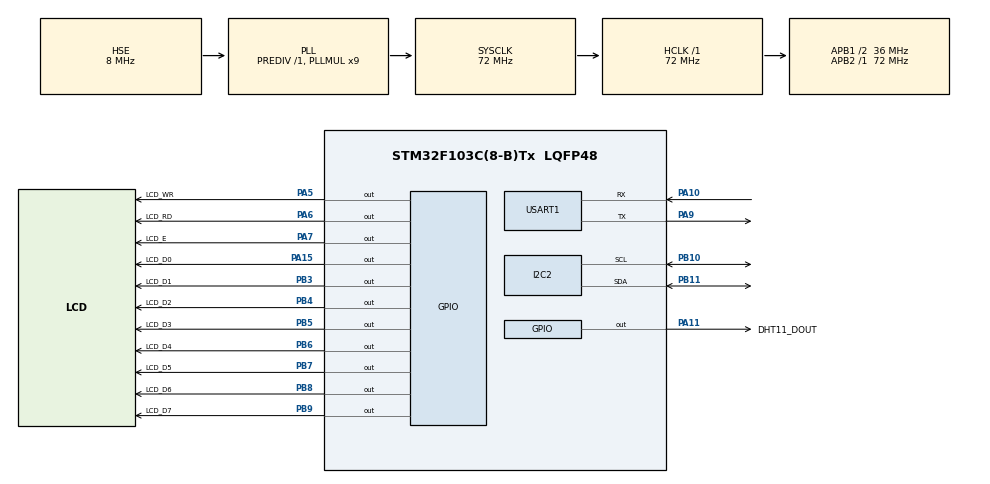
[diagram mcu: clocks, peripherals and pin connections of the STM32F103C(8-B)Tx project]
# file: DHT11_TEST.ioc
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Mcu.Family=STM32F1
Mcu.Name=STM32F103C(8-B)Tx
Mcu.Package=LQFP48
NVIC.PriorityGroup=NVIC_PRIORITYGROUP_4
NVIC.TIM2_IRQn=true\:0\:0\:false\:false\:true\:true\:true
PA10.Mode=Asynchronous
PA10.Signal=USART1_RX
PA11.GPIO_Label=DHT11_DOUT
PA11.GPIO_ModeDefaultOutputPP=GPIO_MODE_OUTPUT_OD
PA11.Signal=GPIO_Output
PA15.GPIO_Label=LCD_D0
PA15.Signal=GPIO_Output
PA5.GPIO_Label=LCD_WR
PA5.Signal=GPIO_Output
PA6.GPIO_Label=LCD_RD
PA6.Signal=GPIO_Output
PA7.GPIO_Label=LCD_E
PA7.Signal=GPIO_Output
PA9.Mode=Asynchronous
PA9.Signal=USART1_TX
PB10.Mode=I2C
PB10.Signal=I2C2_SCL
PB11.Mode=I2C
PB11.Signal=I2C2_SDA
PB3.GPIO_Label=LCD_D1
PB3.Signal=GPIO_Output
PB4.GPIO_Label=LCD_D2
PB4.Signal=GPIO_Output
PB5.GPIO_Label=LCD_D3
PB5.Signal=GPIO_Output
PB6.GPIO_Label=LCD_D4
PB6.Signal=GPIO_Output
PB7.GPIO_Label=LCD_D5
PB7.Signal=GPIO_Output
PB8.GPIO_Label=LCD_D6
PB8.Signal=GPIO_Output
PB9.GPIO_Label=LCD_D7
PB9.Signal=GPIO_Output
PD0-OSC_IN.Mode=HSE-External-Oscillator
PD0-OSC_IN.Signal=RCC_OSC_IN
PD1-OSC_OUT.Mode=HSE-External-Oscillator
PD1-OSC_OUT.Signal=RCC_OSC_OUT
ProjectManager.HeapSize=0x200
ProjectManager.StackSize=0x400
ProjectManager.TargetToolchain=STM32CubeIDE
RCC.AHBFreq_Value=72000000
RCC.APB1CLKDivider=RCC_HCLK_DIV2
RCC.APB1Freq_Value=36000000
RCC.APB1TimFreq_Value=72000000
RCC.APB2Freq_Value=72000000
RCC.APB2TimFreq_Value=72000000
RCC.HCLKFreq_Value=72000000
RCC.PLLMUL=RCC_PLL_MUL9
RCC.PLLSourceVirtual=RCC_PLLSOURCE_HSE
RCC.SYSCLKFreq_VALUE=72000000
RCC.SYSCLKSource=RCC_SYSCLKSOURCE_PLLCLK
RCC.USBFreq_Value=72000000
USART1.VirtualMode=VM_ASYNC
VP_SYS_VS_ND.Mode=No_Debug
VP_TIM2_VS_ClockSourceINT.Mode=Internal
board=custom

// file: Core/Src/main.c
/* USER CODE BEGIN Header */
/**
  ******************************************************************************
  * @file           : main.c
  * @brief          : Main program body
  ******************************************************************************
  * @attention
  *
  * <h2><center>&copy; Copyright (c) 2020 STMicroelectronics.
  * All rights reserved.</center></h2>
  *
  * This software component is licensed by ST under BSD 3-Clause license,
  * the "License"; You may not use this file except in compliance with the
  * License. You may obtain a copy of the License at:
  *                        opensource.org/licenses/BSD-3-Clause
  *
  ******************************************************************************
  */
/* USER CODE END Header */
#include "main.h"

I2C_HandleTypeDef hi2c2;

TIM_HandleTypeDef htim2;

UART_HandleTypeDef huart1;

/* USER CODE BEGIN PV */
extern uint8_t dht11_data[5];
/* USER CODE END PV */

void SystemClock_Config(void);
static void MX_GPIO_Init(void);
static void MX_I2C2_Init(void);
static void MX_TIM2_Init(void);
static void MX_USART1_UART_Init(void);

int main(void)
{

  /* MCU Configuration--------------------------------------------------------*/

  /* Reset of all peripherals, Initializes the Flash interface and the Systick. */
  HAL_Init();

  /* Configure the system clock */
  SystemClock_Config();

  /* Initialize all configured peripherals */
  MX_GPIO_Init();
  MX_I2C2_Init();
  MX_TIM2_Init();
  MX_USART1_UART_Init();
  /* USER CODE BEGIN 2 */

  lcd_init();
  /* USER CODE END 2 */

  /* Infinite loop */
  while (1)
  {

	  lcd_writeCom(0x80);

	  DHT11_read();
	  lcd_show_dht11(dht11_data);

	  lcd_writeCom(0x80|0x40);

	  lcd_show_gy30(GY30_read());

	  HAL_Delay(1000);
  }
}

void SystemClock_Config(void)
{
  RCC_OscInitTypeDef RCC_OscInitStruct = {0};
  RCC_ClkInitTypeDef RCC_ClkInitStruct = {0};

  /** Initializes the RCC Oscillators according to the specified parameters
  * in the RCC_OscInitTypeDef structure.
  */
  RCC_OscInitStruct.OscillatorType = RCC_OSCILLATORTYPE_HSE;
  RCC_OscInitStruct.HSEState = RCC_HSE_ON;
  RCC_OscInitStruct.HSEPredivValue = RCC_HSE_PREDIV_DIV1;
  RCC_OscInitStruct.HSIState = RCC_HSI_ON;
  RCC_OscInitStruct.PLL.PLLState = RCC_PLL_ON;
  RCC_OscInitStruct.PLL.PLLSource = RCC_PLLSOURCE_HSE;
  RCC_OscInitStruct.PLL.PLLMUL = RCC_PLL_MUL9;
  if (HAL_RCC_OscConfig(&RCC_OscInitStruct) != HAL_OK)
  {
    Error_Handler();
  }
  /** Initializes the CPU, AHB and APB buses clocks
  */
  RCC_ClkInitStruct.ClockType = RCC_CLOCKTYPE_HCLK|RCC_CLOCKTYPE_SYSCLK
                              |RCC_CLOCKTYPE_PCLK1|RCC_CLOCKTYPE_PCLK2;
  RCC_ClkInitStruct.SYSCLKSource = RCC_SYSCLKSOURCE_PLLCLK;
  RCC_ClkInitStruct.AHBCLKDivider = RCC_SYSCLK_DIV1;
  RCC_ClkInitStruct.APB1CLKDivider = RCC_HCLK_DIV2;
  RCC_ClkInitStruct.APB2CLKDivider = RCC_HCLK_DIV1;

  if (HAL_RCC_ClockConfig(&RCC_ClkInitStruct, FLASH_LATENCY_2) != HAL_OK)
  {
    Error_Handler();
  }
}

static void MX_I2C2_Init(void)
{

  hi2c2.Instance = I2C2;
  hi2c2.Init.ClockSpeed = 100000;
  hi2c2.Init.DutyCycle = I2C_DUTYCYCLE_2;
  hi2c2.Init.OwnAddress1 = 0;
  hi2c2.Init.AddressingMode = I2C_ADDRESSINGMODE_7BIT;
  hi2c2.Init.DualAddressMode = I2C_DUALADDRESS_DISABLE;
  hi2c2.Init.OwnAddress2 = 0;
  hi2c2.Init.GeneralCallMode = I2C_GENERALCALL_DISABLE;
  hi2c2.Init.NoStretchMode = I2C_NOSTRETCH_DISABLE;
  if (HAL_I2C_Init(&hi2c2) != HAL_OK)
  {
    Error_Handler();
  }

}

static void MX_TIM2_Init(void)
{

  TIM_ClockConfigTypeDef sClockSourceConfig = {0};
  TIM_MasterConfigTypeDef sMasterConfig = {0};

  htim2.Instance = TIM2;
  htim2.Init.Prescaler = 0;
  htim2.Init.CounterMode = TIM_COUNTERMODE_UP;
  htim2.Init.Period = 65535;
  htim2.Init.ClockDivision = TIM_CLOCKDIVISION_DIV1;
  htim2.Init.AutoReloadPreload = TIM_AUTORELOAD_PRELOAD_DISABLE;
  if (HAL_TIM_Base_Init(&htim2) != HAL_OK)
  {
    Error_Handler();
  }
  sClockSourceConfig.ClockSource = TIM_CLOCKSOURCE_INTERNAL;
  if (HAL_TIM_ConfigClockSource(&htim2, &sClockSourceConfig) != HAL_OK)
  {
    Error_Handler();
  }
  sMasterConfig.MasterOutputTrigger = TIM_TRGO_RESET;
  sMasterConfig.MasterSlaveMode = TIM_MASTERSLAVEMODE_DISABLE;
  if (HAL_TIMEx_MasterConfigSynchronization(&htim2, &sMasterConfig) != HAL_OK)
  {
    Error_Handler();
  }

}

static void MX_USART1_UART_Init(void)
{

  huart1.Instance = USART1;
  huart1.Init.BaudRate = 115200;
  huart1.Init.WordLength = UART_WORDLENGTH_8B;
  huart1.Init.StopBits = UART_STOPBITS_1;
  huart1.Init.Parity = UART_PARITY_NONE;
  huart1.Init.Mode = UART_MODE_TX_RX;
  huart1.Init.HwFlowCtl = UART_HWCONTROL_NONE;
  huart1.Init.OverSampling = UART_OVERSAMPLING_16;
  if (HAL_UART_Init(&huart1) != HAL_OK)
  {
    Error_Handler();
  }

}

static void MX_GPIO_Init(void)
{
  GPIO_InitTypeDef GPIO_InitStruct = {0};

  /* GPIO Ports Clock Enable */
  __HAL_RCC_GPIOD_CLK_ENABLE();
  __HAL_RCC_GPIOA_CLK_ENABLE();
  __HAL_RCC_GPIOB_CLK_ENABLE();

  /*Configure GPIO pin Output Level */
  HAL_GPIO_WritePin(GPIOA, LCD_WR_Pin|LCD_RD_Pin|LCD_E_Pin|DHT11_DOUT_Pin
                          |LCD_D0_Pin, GPIO_PIN_RESET);

  /*Configure GPIO pin Output Level */
  HAL_GPIO_WritePin(GPIOB, LCD_D1_Pin|LCD_D2_Pin|LCD_D3_Pin|LCD_D4_Pin
                          |LCD_D5_Pin|LCD_D6_Pin|LCD_D7_Pin, GPIO_PIN_RESET);

  /*Configure GPIO pins : LCD_WR_Pin LCD_RD_Pin LCD_E_Pin LCD_D0_Pin */
  GPIO_InitStruct.Pin = LCD_WR_Pin|LCD_RD_Pin|LCD_E_Pin|LCD_D0_Pin;
  GPIO_InitStruct.Mode = GPIO_MODE_OUTPUT_PP;
  GPIO_InitStruct.Pull = GPIO_NOPULL;
  GPIO_InitStruct.Speed = GPIO_SPEED_FREQ_LOW;
  HAL_GPIO_Init(GPIOA, &GPIO_InitStruct);

  /*Configure GPIO pin : DHT11_DOUT_Pin */
  GPIO_InitStruct.Pin = DHT11_DOUT_Pin;
  GPIO_InitStruct.Mode = GPIO_MODE_OUTPUT_OD;
  GPIO_InitStruct.Pull = GPIO_NOPULL;
  GPIO_InitStruct.Speed = GPIO_SPEED_FREQ_LOW;
  HAL_GPIO_Init(DHT11_DOUT_GPIO_Port, &GPIO_InitStruct);

  /*Configure GPIO pins : LCD_D1_Pin LCD_D2_Pin LCD_D3_Pin LCD_D4_Pin
                           LCD_D5_Pin LCD_D6_Pin LCD_D7_Pin */
  GPIO_InitStruct.Pin = LCD_D1_Pin|LCD_D2_Pin|LCD_D3_Pin|LCD_D4_Pin
                          |LCD_D5_Pin|LCD_D6_Pin|LCD_D7_Pin;
  GPIO_InitStruct.Mode = GPIO_MODE_OUTPUT_PP;
  GPIO_InitStruct.Pull = GPIO_NOPULL;
  GPIO_InitStruct.Speed = GPIO_SPEED_FREQ_LOW;
  HAL_GPIO_Init(GPIOB, &GPIO_InitStruct);

}

void Error_Handler(void)
{
}

/************************ (C) COPYRIGHT STMicroelectronics *****END OF FILE****/
